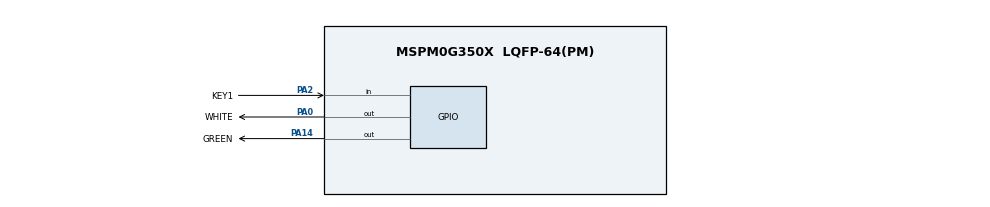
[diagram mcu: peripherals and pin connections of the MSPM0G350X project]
/**
 * @cliArgs --device "MSPM0G350X" --package "LQFP-64(PM)" --part "Default" --product "mspm0_sdk@1.30.00.03"
 * @versions {"tool":"1.19.0+3426"}
 */

/**
 * Import the modules used in this configuration.
 */
const GPIO   = scripting.addModule("/ti/driverlib/GPIO", {}, false);
const GPIO1  = GPIO.addInstance();
const GPIO2  = GPIO.addInstance();
const SYSCTL = scripting.addModule("/ti/driverlib/SYSCTL");

/**
 * Write custom configuration values to the imported modules.
 */
const divider9       = system.clockTree["UDIV"];
divider9.divideValue = 2;

const multiplier2         = system.clockTree["PLL_QDIV"];
multiplier2.multiplyValue = 4;

const mux4       = system.clockTree["EXHFMUX"];
mux4.inputSelect = "EXHFMUX_XTAL";

const mux8       = system.clockTree["HSCLKMUX"];
mux8.inputSelect = "HSCLKMUX_SYSPLL0";

const mux12       = system.clockTree["SYSPLLMUX"];
mux12.inputSelect = "zSYSPLLMUX_HFCLK";

const pinFunction4       = system.clockTree["HFXT"];
pinFunction4.enable      = true;
pinFunction4.inputFreq   = 40;
pinFunction4.HFXTStartup = 10;

GPIO1.port                          = "PORTA";
GPIO1.$name                         = "LED";
GPIO1.associatedPins.create(2);
GPIO1.associatedPins[0].$name       = "WHITE";
GPIO1.associatedPins[0].assignedPin = "0";
GPIO1.associatedPins[0].pin.$assign = "PA0";
GPIO1.associatedPins[1].$name       = "GREEN";
GPIO1.associatedPins[1].assignedPin = "14";
GPIO1.associatedPins[1].pin.$assign = "PA14";

const Board = scripting.addModule("/ti/driverlib/Board", {}, false);

GPIO2.$name                                 = "KEY";
GPIO2.port                                  = "PORTA";
GPIO2.associatedPins[0].$name               = "KEY1";
GPIO2.associatedPins[0].direction           = "INPUT";
GPIO2.associatedPins[0].assignedPortSegment = "Lower";
GPIO2.associatedPins[0].assignedPin         = "2";
GPIO2.associatedPins[0].pin.$assign         = "PA2";

SYSCTL.forceDefaultClkConfig = true;
SYSCTL.clockTreeEn           = true;

/**
 * Pinmux solution for unlocked pins/peripherals. This ensures that minor changes to the automatic solver in a future
 * version of the tool will not impact the pinmux you originally saw.  These lines can be completely deleted in order to
 * re-solve from scratch.
 */
pinFunction4.peripheral.$suggestSolution           = "SYSCTL";
pinFunction4.peripheral.hfxInPin.$suggestSolution  = "PA5";
pinFunction4.peripheral.hfxOutPin.$suggestSolution = "PA6";
Board.peripheral.$suggestSolution                  = "DEBUGSS";
Board.peripheral.swclkPin.$suggestSolution         = "PA20";
Board.peripheral.swdioPin.$suggestSolution         = "PA19";
